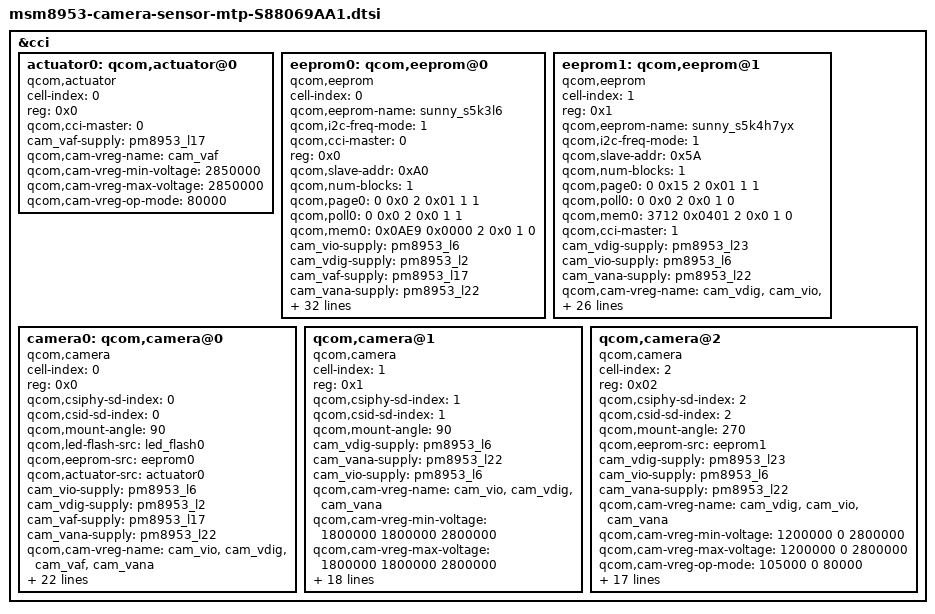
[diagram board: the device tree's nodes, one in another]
/***********************************************************
** Copyright (C), 2008-2016, OPPO Mobile Comm Corp., Ltd.
** ODM_WT_EDIT
** File: - msm8953-camera-sensor-mtp-S88069AA1.dtsi
** Description: source camera sensor config for S88069AA1 in kernel
**
** Version: 1.0
** Date : 2018/12/27
**
** ------------------------------- Revision History: -------------------------------
**  	<author>		<data> 	   <version >	       <desc>
**
****************************************************************/

&cci {
	actuator0: qcom,actuator@0 {
		cell-index = <0>;
		reg = <0x0>;
		compatible = "qcom,actuator";
		qcom,cci-master = <0>;
		cam_vaf-supply = <&pm8953_l17>;
		qcom,cam-vreg-name = "cam_vaf";
		qcom,cam-vreg-min-voltage = <2850000>;
		qcom,cam-vreg-max-voltage = <2850000>;
		qcom,cam-vreg-op-mode = <80000>;
	};

	eeprom0: qcom,eeprom@0 {
		cell-index = <0>;
		qcom,eeprom-name = "sunny_s5k3l6";
		qcom,i2c-freq-mode = <1>;
		compatible = "qcom,eeprom";
		qcom,cci-master = <0>;
		reg = <0x0>;
		qcom,slave-addr = <0xA0>;

		qcom,num-blocks = <1>;
		qcom,page0 = <0 0x0 2 0x01 1 1>;
		qcom,poll0 = <0 0x0 2 0x0 1 1>;
		qcom,mem0 = <0x0AE9 0x0000 2 0x0 1 0>;

		cam_vio-supply = <&pm8953_l6>;
		cam_vdig-supply = <&pm8953_l2>;
		cam_vaf-supply = <&pm8953_l17>;
		cam_vana-supply = <&pm8953_l22>;
		qcom,cam-vreg-name = "cam_vio", "cam_vdig", "cam_vaf",
						"cam_vana";
		qcom,cam-vreg-min-voltage = <0 1050000 2850000 2800000>;
		qcom,cam-vreg-max-voltage = <0 1050000 2850000 2800000>;
		qcom,cam-vreg-op-mode = <0 105000 100000 80000>;
		pinctrl-names = "cam_default", "cam_suspend";
		pinctrl-0 = <&cam_sensor_mclk0_default
				&cam_sensor_rear_default>;
		pinctrl-1 = <&cam_sensor_mclk0_sleep &cam_sensor_rear_sleep>;
		gpios = <&tlmm 26 0>,
			<&tlmm 40 0>,
			<&tlmm 130 0>;
		qcom,gpio-reset = <1>;
		qcom,gpio-standby = <2>;
		//qcom,gpio-vana = <3>;
		qcom,gpio-req-tbl-num = <0 1 2>;
		qcom,gpio-req-tbl-flags = <1 0 0>;
		qcom,gpio-req-tbl-label = "CAMIF_MCLK0",
			"CAM_RESET0",
			"CAM_STANDBY0";
		qcom,cam-power-seq-type = "sensor_gpio", "sensor_gpio", "sensor_vreg",
			"sensor_vreg", "sensor_vreg", "sensor_gpio", "sensor_gpio",
			"sensor_clk" ;
		qcom,cam-power-seq-val = "sensor_gpio_reset", "sensor_gpio_standby",
			"cam_vana", "cam_vdig", "cam_vio", "sensor_gpio_reset",
			"sensor_gpio_standby", "sensor_cam_mclk";
		qcom,cam-power-seq-cfg-val = <0 0 1 1 1 1 1 24000000>;
		qcom,cam-power-seq-delay = <1 1 0 0 1 10 10 10>;
		status = "ok";
		clocks = <&clock_gcc clk_mclk0_clk_src>,
				<&clock_gcc clk_gcc_camss_mclk0_clk>;
		clock-names = "cam_src_clk", "cam_clk";
		qcom,clock-rates = <24000000 0>;
	};

	eeprom1: qcom,eeprom@1 {
		cell-index = <1>;
		reg = <0x1>;
		qcom,eeprom-name = "sunny_s5k4h7yx";
		qcom,i2c-freq-mode = <1>;
		compatible = "qcom,eeprom";
		qcom,slave-addr = <0x5A>;
		qcom,num-blocks = <1>;
		qcom,page0 = <0 0x15 2 0x01 1 1>;
		qcom,poll0 = <0 0x0 2 0x0 1 0>;
		qcom,mem0 = <3712 0x0401 2 0x0 1 0>;

		qcom,cci-master = <1>;
		cam_vdig-supply = <&pm8953_l23>;
		cam_vio-supply = <&pm8953_l6>;
		cam_vana-supply = <&pm8953_l22>;
		qcom,cam-vreg-name = "cam_vdig", "cam_vio", "cam_vana";
		qcom,cam-vreg-min-voltage = <1200000 0 2800000>;
		qcom,cam-vreg-max-voltage = <1200000 0 2800000>;
		qcom,cam-vreg-op-mode = <105000 0 80000>;
		qcom,gpio-no-mux = <0>;
		pinctrl-names = "cam_default", "cam_suspend";
		pinctrl-0 = <&cam_sensor_mclk1_default
					&cam_sensor_front1_default>;
		pinctrl-1 = <&cam_sensor_mclk1_sleep
					&cam_sensor_front1_sleep>;
		gpios = <&tlmm 27 0>,
				<&tlmm 129 0>;
		qcom,gpio-reset = <1>;
		qcom,gpio-req-tbl-num = <0 1>;
		qcom,gpio-req-tbl-flags = <1 0>;
		qcom,gpio-req-tbl-label = "CAMIF_MCLK1",
						"CAM_RESET2";
		qcom,cam-power-seq-type = "sensor_gpio", "sensor_vreg", "sensor_vreg", "sensor_vreg", "sensor_gpio", "sensor_clk" ;
		qcom,cam-power-seq-val = "sensor_gpio_reset", "cam_vdig", "cam_vana", "cam_vio", "sensor_gpio_reset", "sensor_cam_mclk";
		qcom,cam-power-seq-cfg-val = <0 1 1 1 1 24000000>;
		qcom,cam-power-seq-delay = <5 1 1 1 10 20>;
		status = "ok";
		clocks = <&clock_gcc clk_mclk1_clk_src>,
			<&clock_gcc clk_gcc_camss_mclk1_clk>;
		clock-names = "cam_src_clk", "cam_clk";
		qcom,clock-rates = <24000000 0>;
	};

	camera0: qcom,camera@0 {
		cell-index = <0>;
		compatible = "qcom,camera";
		reg = <0x0>;
		qcom,csiphy-sd-index = <0>;
		qcom,csid-sd-index = <0>;
		qcom,mount-angle = <90>;
		qcom,led-flash-src = <&led_flash0>;
		qcom,eeprom-src = <&eeprom0>;
		qcom,actuator-src = <&actuator0>;
		cam_vio-supply = <&pm8953_l6>;
		cam_vdig-supply = <&pm8953_l2>;
		cam_vaf-supply = <&pm8953_l17>;
		cam_vana-supply = <&pm8953_l22>;
		//cam_v_custom1-supply = <&pm8953_l23>;
		qcom,cam-vreg-name = "cam_vio", "cam_vdig", "cam_vaf",
						"cam_vana";
		qcom,cam-vreg-min-voltage = <0 1050000 2850000 2800000>;
		qcom,cam-vreg-max-voltage = <0 1050000 2850000 2800000>;
		qcom,cam-vreg-op-mode = <0 105000 100000 80000>;
		pinctrl-names = "cam_default", "cam_suspend";
		pinctrl-0 = <&cam_sensor_mclk0_default
				&cam_sensor_rear_default>;
		pinctrl-1 = <&cam_sensor_mclk0_sleep &cam_sensor_rear_sleep>;
		gpios = <&tlmm 26 0>,
			<&tlmm 40 0>,
			<&tlmm 130 0>;
		qcom,gpio-reset = <1>;
		qcom,gpio-standby = <2>;
		//qcom,gpio-vana = <3>;
		qcom,gpio-req-tbl-num = <0 1 2>;
		qcom,gpio-req-tbl-flags = <1 0 0>;
		qcom,gpio-req-tbl-label = "CAMIF_MCLK0",
			"CAM_RESET0",
			"CAM_STANDBY0";
		qcom,sensor-position = <0>;
		qcom,sensor-mode = <0>;
		qcom,cci-master = <0>;
		status = "ok";
		clocks = <&clock_gcc clk_mclk0_clk_src>,
				<&clock_gcc clk_gcc_camss_mclk0_clk>;
		clock-names = "cam_src_clk", "cam_clk";
		qcom,clock-rates = <24000000 0>;
	};

	qcom,camera@1 {
		cell-index = <1>;
		compatible = "qcom,camera";
		reg = <0x1>;
		qcom,csiphy-sd-index = <1>;
		qcom,csid-sd-index = <1>;
		qcom,mount-angle = <90>;
		cam_vdig-supply = <&pm8953_l6>;
		cam_vana-supply = <&pm8953_l22>;
		cam_vio-supply = <&pm8953_l6>;
		//cam_vaf-supply = <&pm8953_l17>;
		qcom,cam-vreg-name = "cam_vio", "cam_vdig", "cam_vana";
		qcom,cam-vreg-min-voltage = <1800000 1800000 2800000 >;
		qcom,cam-vreg-max-voltage = <1800000 1800000 2800000 >;
		qcom,cam-vreg-op-mode = <200000 200000 80000 >;
		pinctrl-names = "cam_default", "cam_suspend";
		pinctrl-0 = <&cam_sensor_mclk2_default
				&cam_sensor_front_default>;
		pinctrl-1 = <&cam_sensor_mclk2_sleep
				&cam_sensor_front_sleep>;
		gpios = <&tlmm 28 0>,
			<&tlmm 131 0>,
			<&tlmm 132 0>;
		qcom,gpio-reset = <1>;
		qcom,gpio-standby = <2>;
		qcom,gpio-req-tbl-num = <0 1 2>;
		qcom,gpio-req-tbl-flags = <1 0 0>;
		qcom,gpio-req-tbl-label = "CAMIF_MCLK1",
			"CAM_RESET1",
			"CAM_STANDBY1";
		qcom,sensor-position = <0x100>;
		qcom,sensor-mode = <1>;
		qcom,cci-master = <1>;
		status = "ok";
		clocks = <&clock_gcc clk_mclk2_clk_src>,
				<&clock_gcc clk_gcc_camss_mclk2_clk>;
		clock-names = "cam_src_clk", "cam_clk";
		qcom,clock-rates = <24000000 0>;
	};

	qcom,camera@2 {
		cell-index = <2>;
		compatible = "qcom,camera";
		reg = <0x02>;
		qcom,csiphy-sd-index = <2>;
		qcom,csid-sd-index = <2>;
		qcom,mount-angle = <270>;
		qcom,eeprom-src = <&eeprom1>;
		cam_vdig-supply = <&pm8953_l23>;
		cam_vio-supply = <&pm8953_l6>;
		cam_vana-supply = <&pm8953_l22>;
		qcom,cam-vreg-name = "cam_vdig", "cam_vio", "cam_vana";
		qcom,cam-vreg-min-voltage = <1200000 0 2800000>;
		qcom,cam-vreg-max-voltage = <1200000 0 2800000>;
		qcom,cam-vreg-op-mode = <105000 0 80000>;
		qcom,gpio-no-mux = <0>;
		pinctrl-names = "cam_default", "cam_suspend";
		pinctrl-0 = <&cam_sensor_mclk1_default
				&cam_sensor_front1_default>;
		pinctrl-1 = <&cam_sensor_mclk1_sleep
				&cam_sensor_front1_sleep>;
		gpios = <&tlmm 27 0>,
			<&tlmm 129 0>;
		qcom,gpio-reset = <1>;
		qcom,gpio-req-tbl-num = <0 1>;
		qcom,gpio-req-tbl-flags = <1 0>;
		qcom,gpio-req-tbl-label = "CAMIF_MCLK1",
					  "CAM_RESET2";
		qcom,sensor-position = <1>;
		qcom,sensor-mode = <0>;
		qcom,cci-master = <1>;
		status = "ok";
		clocks = <&clock_gcc clk_mclk1_clk_src>,
			<&clock_gcc clk_gcc_camss_mclk1_clk>;
		clock-names = "cam_src_clk", "cam_clk";
		qcom,clock-rates = <24000000 0>;
	};
};
